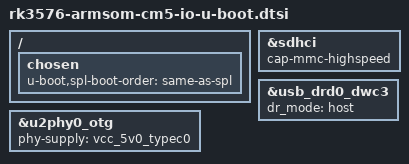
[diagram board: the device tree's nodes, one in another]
// SPDX-License-Identifier: (GPL-2.0+ OR MIT)

#include "rk3576-u-boot.dtsi"

&sdhci {
	cap-mmc-highspeed;
};

/*
 * The Linux DTS runs the USB-C port as OTG behind the FUSB302. U-Boot has
 * no role switch for it, so use host mode to boot from USB-C storage.
 */
&usb_drd0_dwc3 {
	dr_mode = "host";
};

/*
 * U-Boot has no TCPM, so let the USB2 PHY switch on the USB-C VBUS.
 * Linux leaves it to the FUSB302.
 */
&u2phy0_otg {
	phy-supply = <&vcc_5v0_typec0>;
};

/*
 * Not in Armbian's file (everything above is): let the SPL look on the SD
 * card first for its FIT, and fall back to the device it was loaded from,
 * as on the TaishanPi 3M.  The SPL's Armbian one-shot code visits the SD
 * card before the eMMC (docs/ARMBIAN-CHAINLOAD.md), and with the firmware
 * on the eMMC it skips an Armbian FIT on the card unless a request asks
 * for it.  A card that carries this firmware's own FIT does boot from the
 * card.
 */
/ {
	chosen {
		u-boot,spl-boot-order = &sdmmc, "same-as-spl", &sdhci;
	};
};
